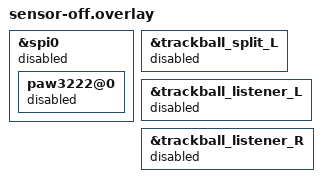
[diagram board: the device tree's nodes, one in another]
/* Apply after the normal PAW3222 snippet. Sensor power is still connected
 * physically; only firmware initialization, SPI and MOTION handling stop.
 */
&spi0 {
    status = "disabled";
    paw3222@0 {
        status = "disabled";
    };
};

&trackball_split_L {
    status = "disabled";
};

&trackball_listener_L {
    status = "disabled";
};

&trackball_listener_R {
    status = "disabled";
};
